# PIC32MK0512GPL064 register map
Vendor: Microchip
Registers are 32-bit, read-write, no defined reset value unless marked. A register's access mark holds for its fields unless they carry their own. Addresses are absolute, and some are shared; only a register's first bit layout is shown; [hi:lo] are bit positions; {n}, {i} and the like mark numbered series.

## PORTC
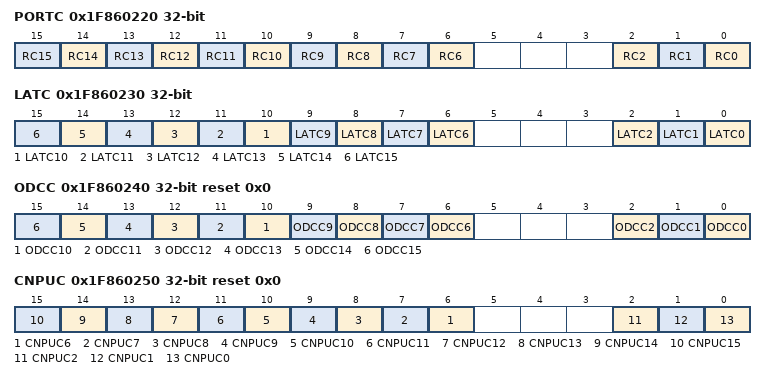
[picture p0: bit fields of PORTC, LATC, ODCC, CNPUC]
0x1F860220 PORTC — (power-on value ----------------xxxxxxxxxx---xxx)
  [n] RC{n} (n=6..15), [2] RC2, [1] RC1, [0] RC0
0x1F860230 LATC — (power-on value ----------------xxxxxxxxxx---xxx)
  [n] LATC{n} (n=6..15), [2] LATC2, [1] LATC1, [0] LATC0
0x1F860240 ODCC reset 0x0
  [n] ODCC{n} (n=6..15), [2] ODCC2, [1] ODCC1, [0] ODCC0
0x1F860250 CNPUC reset 0x0
  [n] CNPUC{n} (n=6..15), [2] CNPUC2, [1] CNPUC1, [0] CNPUC0
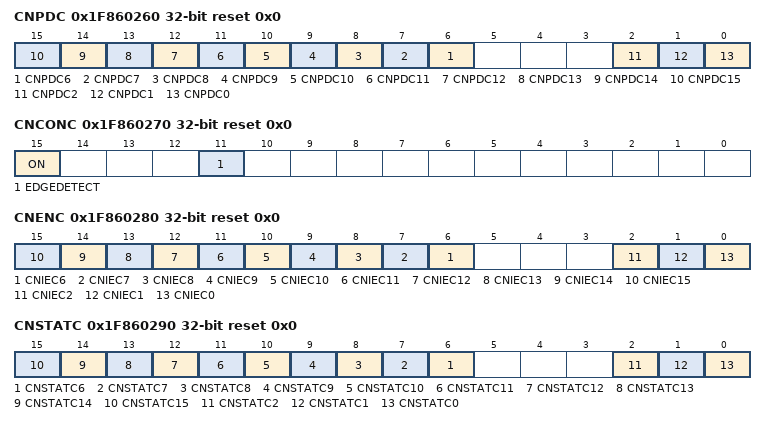
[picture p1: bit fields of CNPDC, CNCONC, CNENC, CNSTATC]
0x1F860260 CNPDC reset 0x0
  [n] CNPDC{n} (n=6..15), [2] CNPDC2, [1] CNPDC1, [0] CNPDC0
0x1F860270 CNCONC reset 0x0
  [15] ON, [11] EDGEDETECT
0x1F860280 CNENC reset 0x0
  [n] CNIEC{n} (n=6..15), [2] CNIEC2, [1] CNIEC1, [0] CNIEC0
0x1F860290 CNSTATC reset 0x0
  [n] CNSTATC{n} (n=6..15), [2] CNSTATC2, [1] CNSTATC1, [0] CNSTATC0
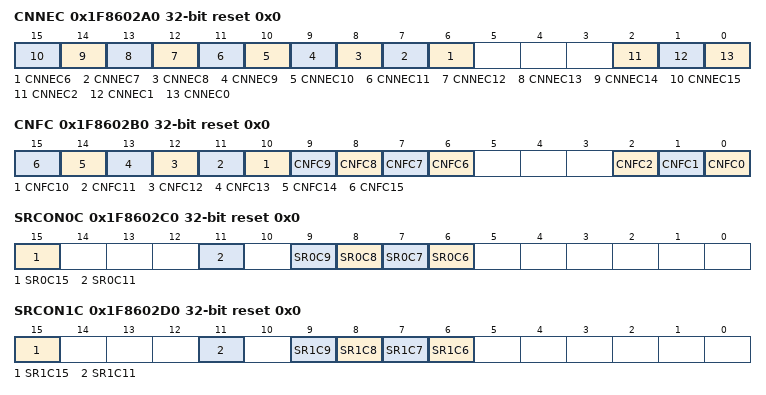
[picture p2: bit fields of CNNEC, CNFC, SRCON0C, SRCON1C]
0x1F8602A0 CNNEC reset 0x0
  [n] CNNEC{n} (n=6..15), [2] CNNEC2, [1] CNNEC1, [0] CNNEC0
0x1F8602B0 CNFC reset 0x0
  [n] CNFC{n} (n=6..15), [2] CNFC2, [1] CNFC1, [0] CNFC0
0x1F8602C0 SRCON0C reset 0x0
  [15] SR0C15, [11] SR0C11, [n] SR0C{n} (n=6..9)
0x1F8602D0 SRCON1C reset 0x0
  [15] SR1C15, [11] SR1C11, [n] SR1C{n} (n=6..9)

## PORTD
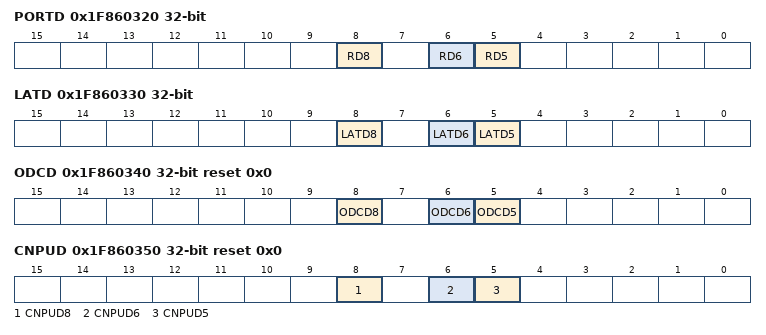
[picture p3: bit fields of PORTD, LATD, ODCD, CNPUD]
0x1F860320 PORTD — (power-on value -----------------------x-xx-----)
  [8] RD8, [6] RD6, [5] RD5
0x1F860330 LATD — (power-on value -----------------------x-xx-----)
  [8] LATD8, [6] LATD6, [5] LATD5
0x1F860340 ODCD reset 0x0
  [8] ODCD8, [6] ODCD6, [5] ODCD5
0x1F860350 CNPUD reset 0x0
  [8] CNPUD8, [6] CNPUD6, [5] CNPUD5
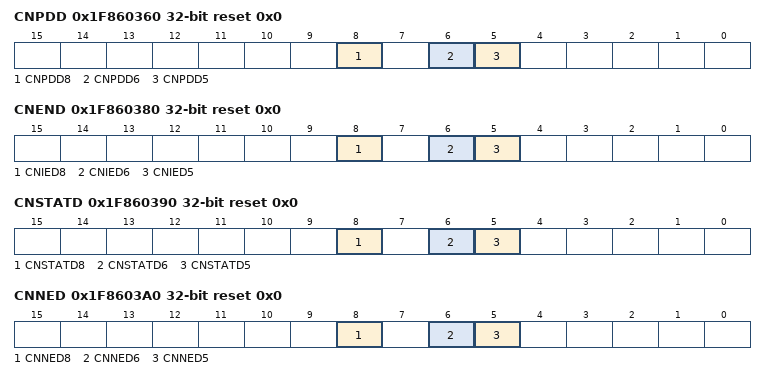
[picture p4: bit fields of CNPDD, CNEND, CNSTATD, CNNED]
0x1F860360 CNPDD reset 0x0
  [8] CNPDD8, [6] CNPDD6, [5] CNPDD5
0x1F860370 CNCOND access not given
0x1F860380 CNEND reset 0x0
  [8] CNIED8, [6] CNIED6, [5] CNIED5
0x1F860390 CNSTATD reset 0x0
  [8] CNSTATD8, [6] CNSTATD6, [5] CNSTATD5
0x1F8603A0 CNNED reset 0x0
  [8] CNNED8, [6] CNNED6, [5] CNNED5
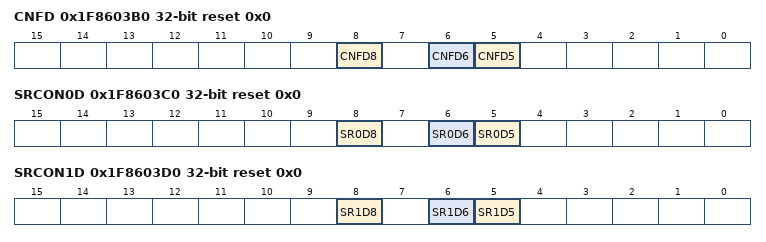
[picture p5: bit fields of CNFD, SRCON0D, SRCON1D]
0x1F8603B0 CNFD reset 0x0
  [8] CNFD8, [6] CNFD6, [5] CNFD5
0x1F8603C0 SRCON0D reset 0x0
  [8] SR0D8, [6] SR0D6, [5] SR0D5
0x1F8603D0 SRCON1D reset 0x0
  [8] SR1D8, [6] SR1D6, [5] SR1D5

## PORTE
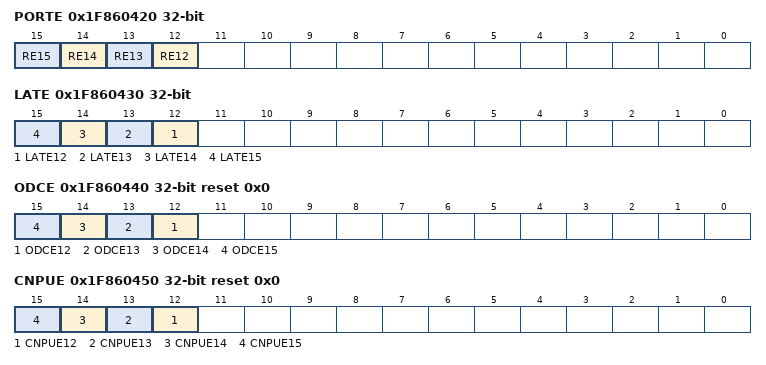
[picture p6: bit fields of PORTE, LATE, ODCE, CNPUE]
0x1F860420 PORTE — (power-on value ----------------xxxx------------)
  [n] RE{n} (n=12..15)
0x1F860430 LATE — (power-on value ----------------xxxx------------)
  [n] LATE{n} (n=12..15)
0x1F860440 ODCE reset 0x0
  [n] ODCE{n} (n=12..15)
0x1F860450 CNPUE reset 0x0
  [n] CNPUE{n} (n=12..15)
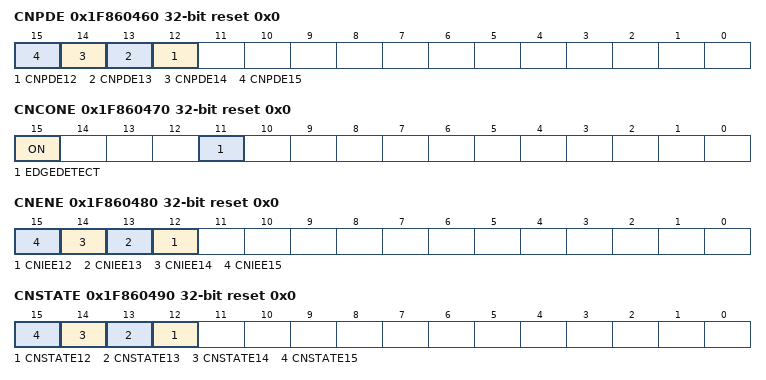
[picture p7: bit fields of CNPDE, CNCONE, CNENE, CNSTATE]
0x1F860460 CNPDE reset 0x0
  [n] CNPDE{n} (n=12..15)
0x1F860470 CNCONE reset 0x0
  [15] ON, [11] EDGEDETECT
0x1F860480 CNENE reset 0x0
  [n] CNIEE{n} (n=12..15)
0x1F860490 CNSTATE reset 0x0
  [n] CNSTATE{n} (n=12..15)
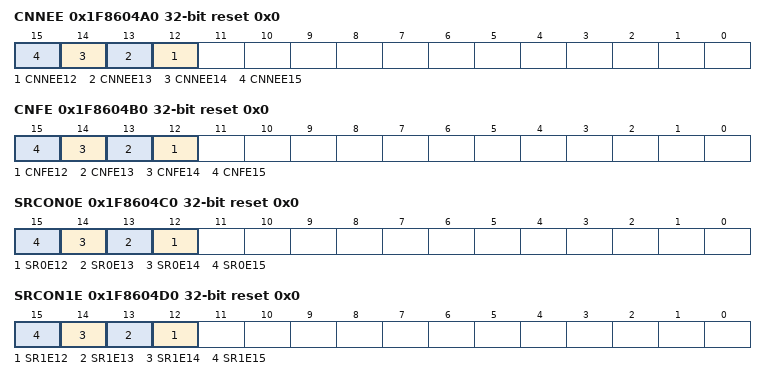
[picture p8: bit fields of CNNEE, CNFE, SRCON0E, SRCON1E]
0x1F8604A0 CNNEE reset 0x0
  [n] CNNEE{n} (n=12..15)
0x1F8604B0 CNFE reset 0x0
  [n] CNFE{n} (n=12..15)
0x1F8604C0 SRCON0E reset 0x0
  [n] SR0E{n} (n=12..15)
0x1F8604D0 SRCON1E reset 0x0
  [n] SR1E{n} (n=12..15)

## PORTF
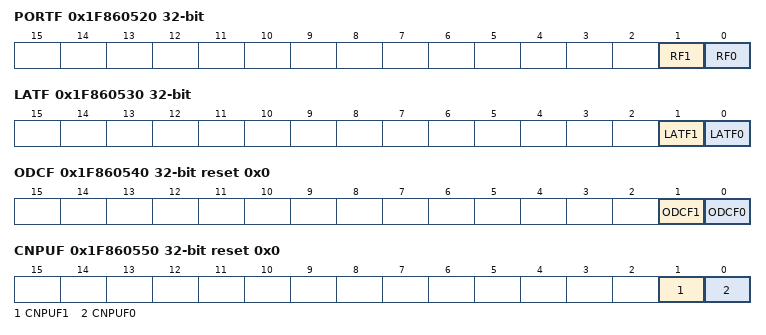
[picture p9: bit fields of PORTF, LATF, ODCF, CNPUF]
0x1F860520 PORTF — (power-on value ------------------------------xx)
  [1] RF1, [0] RF0
0x1F860530 LATF — (power-on value ------------------------------xx)
  [1] LATF1, [0] LATF0
0x1F860540 ODCF reset 0x0
  [1] ODCF1, [0] ODCF0
0x1F860550 CNPUF reset 0x0
  [1] CNPUF1, [0] CNPUF0
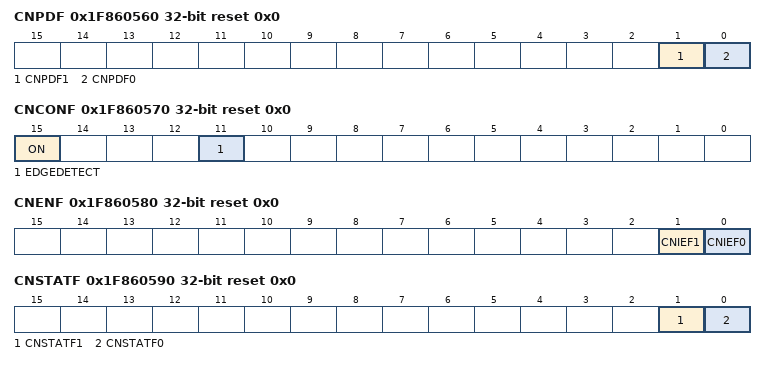
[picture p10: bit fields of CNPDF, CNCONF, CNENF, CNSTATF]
0x1F860560 CNPDF reset 0x0
  [1] CNPDF1, [0] CNPDF0
0x1F860570 CNCONF reset 0x0
  [15] ON, [11] EDGEDETECT
0x1F860580 CNENF reset 0x0
  [1] CNIEF1, [0] CNIEF0
0x1F860590 CNSTATF reset 0x0
  [1] CNSTATF1, [0] CNSTATF0
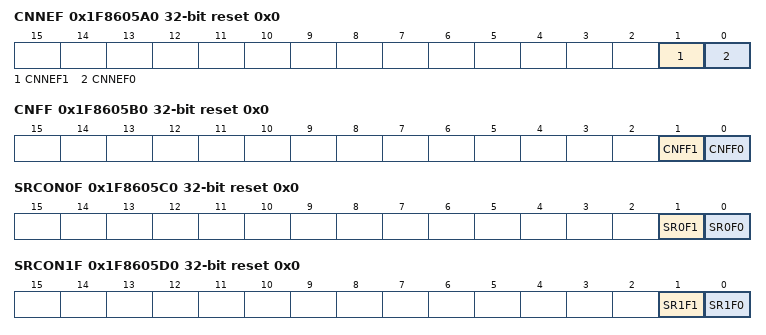
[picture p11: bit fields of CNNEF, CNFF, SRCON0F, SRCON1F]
0x1F8605A0 CNNEF reset 0x0
  [1] CNNEF1, [0] CNNEF0
0x1F8605B0 CNFF reset 0x0
  [1] CNFF1, [0] CNFF0
0x1F8605C0 SRCON0F reset 0x0
  [1] SR0F1, [0] SR0F0
0x1F8605D0 SRCON1F reset 0x0
  [1] SR1F1, [0] SR1F0

## PORTG
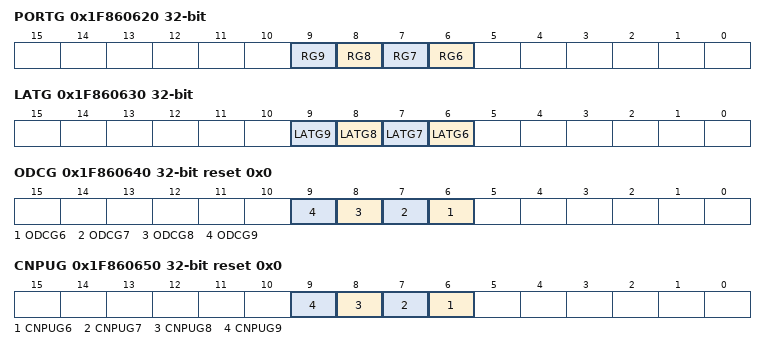
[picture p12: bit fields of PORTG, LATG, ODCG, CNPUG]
0x1F860620 PORTG — (power-on value ----------------------xxxx------)
  [n] RG{n} (n=6..9)
0x1F860630 LATG — (power-on value ----------------------xxxx------)
  [n] LATG{n} (n=6..9)
0x1F860640 ODCG reset 0x0
  [n] ODCG{n} (n=6..9)
0x1F860650 CNPUG reset 0x0
  [n] CNPUG{n} (n=6..9)
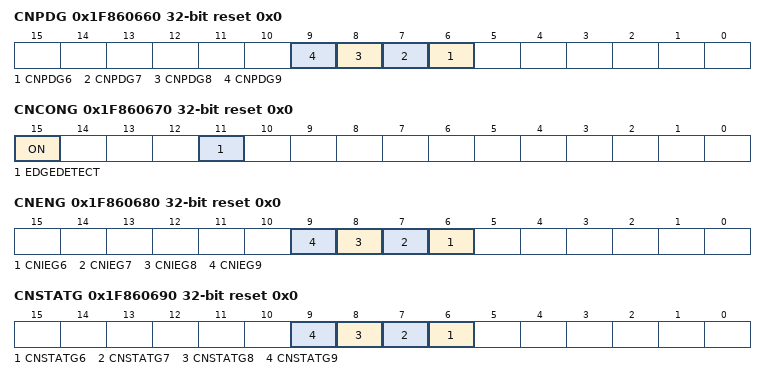
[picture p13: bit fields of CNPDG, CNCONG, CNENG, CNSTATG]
0x1F860660 CNPDG reset 0x0
  [n] CNPDG{n} (n=6..9)
0x1F860670 CNCONG reset 0x0
  [15] ON, [11] EDGEDETECT
0x1F860680 CNENG reset 0x0
  [n] CNIEG{n} (n=6..9)
0x1F860690 CNSTATG reset 0x0
  [n] CNSTATG{n} (n=6..9)
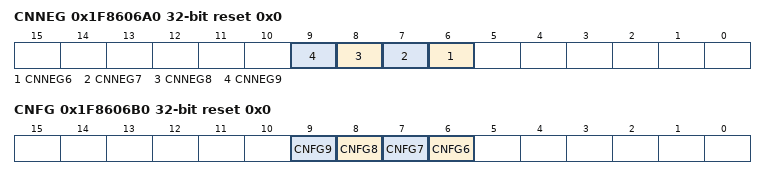
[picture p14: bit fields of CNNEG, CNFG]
0x1F8606A0 CNNEG reset 0x0
  [n] CNNEG{n} (n=6..9)
0x1F8606B0 CNFG reset 0x0
  [n] CNFG{n} (n=6..9)
